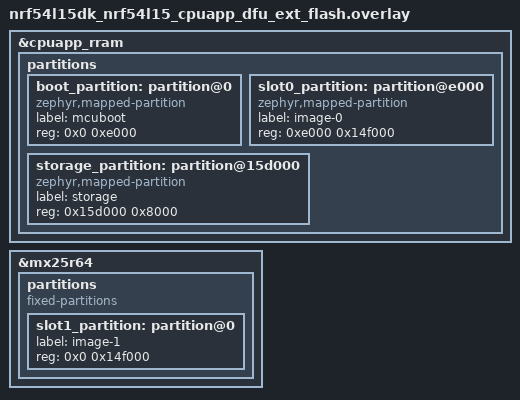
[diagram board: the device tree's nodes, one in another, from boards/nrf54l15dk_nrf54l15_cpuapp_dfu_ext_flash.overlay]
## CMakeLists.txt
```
# SPDX-License-Identifier: LicenseRef-Nordic-5-Clause

cmake_minimum_required(VERSION 3.13.1)
find_package(Zephyr REQUIRED HINTS $ENV{ZEPHYR_BASE})
project(mesh_dfu_distributor)

set(dfu_common_dir ${ZEPHYR_NRF_MODULE_DIR}/samples/bluetooth/mesh/dfu/common/src)

include_directories(
  ${dfu_common_dir}
  ${ZEPHYR_NRF_MODULE_DIR}/samples/bluetooth/mesh/common
)

FILE(GLOB app_sources src/*.c)
target_sources(app PRIVATE ${app_sources}
  ${ZEPHYR_NRF_MODULE_DIR}/samples/bluetooth/mesh/common/smp_bt.c
  ${ZEPHYR_NRF_MODULE_DIR}/samples/bluetooth/mesh/common/mgmt_dfu_hooks.c
  ${dfu_common_dir}/dfu_target.c
)

# Enable authentication with passkey
if(CONFIG_MCUMGR_TRANSPORT_BT_PERM_RW_AUTHEN AND CONFIG_BT_MESH_LE_PAIR_RESP)
  target_sources(app PRIVATE ${ZEPHYR_NRF_MODULE_DIR}/samples/bluetooth/mesh/common/smp_bt_auth.c)
endif()

target_link_libraries(app PRIVATE MCUBOOT_BOOTUTIL)
```

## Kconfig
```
source "Kconfig.zephyr"

source "${ZEPHYR_NRF_MODULE_DIR}/samples/bluetooth/mesh/common/Kconfig"
```

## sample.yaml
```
sample:
  name: Bluetooth Mesh DFU Distributor
common:
  tags:
    - bluetooth
    - ci_build
    - sysbuild
    - ci_samples_bluetooth
tests:
  sample.bluetooth.mesh_dfu_distributor:
    sysbuild: true
    build_only: true
    integration_platforms:
      - nrf54l15dk/nrf54l15/cpuapp
    platform_allow:
      - nrf54l15dk/nrf54l15/cpuapp
      - nrf54l15dk/nrf54l10/cpuapp
      - nrf54lm20dk/nrf54lm20a/cpuapp
  sample.bluetooth.mesh_dfu_distributor.smp_bt_auth:
    sysbuild: true
    build_only: true
    integration_platforms:
      - nrf54l15dk/nrf54l15/cpuapp
    platform_allow:
      - nrf54l15dk/nrf54l15/cpuapp
      - nrf54l15dk/nrf54l10/cpuapp
      - nrf54lm20dk/nrf54lm20a/cpuapp
    extra_args: OVERLAY_CONFIG=overlay-smp-bt-auth.conf
  sample.bluetooth.mesh_dfu_distributor.dfu_ext_flash:
    sysbuild: true
    build_only: true
    integration_platforms:
      - nrf54l15dk/nrf54l15/cpuapp
    platform_allow:
      - nrf54l15dk/nrf54l15/cpuapp
    extra_args: FILE_SUFFIX=dfu_ext_flash
  sample.bluetooth.mesh_dfu_distributor.settings_ext_flash:
    sysbuild: true
    build_only: true
    integration_platforms:
      - nrf54l15dk/nrf54l15/cpuapp
    platform_allow:
      - nrf54l15dk/nrf54l15/cpuapp
      - nrf54l15dk/nrf54l10/cpuapp
    extra_args: FILE_SUFFIX=settings_ext_flash
```

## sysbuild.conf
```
#
# Copyright (c) 2023 Nordic Semiconductor
#
# SPDX-License-Identifier: LicenseRef-Nordic-5-Clause
#

SB_CONFIG_BOOTLOADER_MCUBOOT=y
SB_CONFIG_DFU_ZIP=y
SB_CONFIG_DFU_ZIP_BLUETOOTH_MESH_METADATA=y
SB_CONFIG_DFU_ZIP_BLUETOOTH_MESH_METADATA_FWID_MCUBOOT_VERSION=y
```

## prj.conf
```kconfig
#
# Copyright (c) 2022 Nordic Semiconductor ASA
#
# SPDX-License-Identifier: LicenseRef-Nordic-5-Clause
#

# General configuration
CONFIG_SYSTEM_WORKQUEUE_STACK_SIZE=2048
CONFIG_NVS=y
CONFIG_SETTINGS=y
CONFIG_NVS_LOOKUP_CACHE=y
CONFIG_SETTINGS_NVS_NAME_CACHE=y
CONFIG_HWINFO=y
CONFIG_DK_LIBRARY=y
CONFIG_LOG=y

# Bootloader configuration
CONFIG_NCS_APPLICATION_BOOT_BANNER_STRING="Mesh DFU Distributor"
CONFIG_BOOTLOADER_MCUBOOT=y
CONFIG_NCS_SAMPLE_MCUMGR_BT_OTA_DFU=y
CONFIG_MCUMGR_TRANSPORT_WORKQUEUE_STACK_SIZE=3072
CONFIG_MCUBOOT_GENERATE_CONFIRMED_IMAGE=y
CONFIG_MCUBOOT_IMGTOOL_SIGN_VERSION="1.0.0+0"

# Enable MCUmgr command hooks for doing mesh reset when doing dfu upgrade and storage erase
CONFIG_MCUMGR_MGMT_NOTIFICATION_HOOKS=y
CONFIG_MCUMGR_SMP_COMMAND_STATUS_HOOKS=y
CONFIG_MCUMGR_GRP_OS_RESET_HOOK=y

# Bluetooth configuration
CONFIG_BT=y
CONFIG_BT_DEVICE_NAME="Mesh DFU Distributor"
CONFIG_BT_L2CAP_TX_BUF_COUNT=8
CONFIG_BT_OBSERVER=y
CONFIG_BT_PERIPHERAL=y
CONFIG_BT_SETTINGS=y
CONFIG_BT_BUF_CMD_TX_COUNT=4

# Disable unused Bluetooth features
CONFIG_BT_CTLR_LE_ENC=n
CONFIG_BT_DATA_LEN_UPDATE=n
CONFIG_BT_PHY_UPDATE=n
CONFIG_BT_CTLR_CHAN_SEL_2=n
CONFIG_BT_CTLR_PRIVACY=n
CONFIG_BT_CTLR_PHY_2M=n

# Bluetooth Mesh configuration
CONFIG_BT_MESH=y
CONFIG_BT_MESH_RELAY=y
CONFIG_BT_MESH_FRIEND=y
CONFIG_BT_MESH_MSG_CACHE_SIZE=256
CONFIG_BT_MESH_ADV_BUF_COUNT=128
CONFIG_BT_MESH_TX_SEG_MAX=14
CONFIG_BT_MESH_RX_SEG_MAX=14
CONFIG_BT_MESH_TX_SEG_MSG_COUNT=2
CONFIG_BT_MESH_RX_SEG_MSG_COUNT=2
CONFIG_BT_MESH_PB_GATT=y
CONFIG_BT_MESH_PB_ADV=y
CONFIG_BT_MESH_GATT_PROXY=y
CONFIG_BT_MESH_SHELL=y
CONFIG_BT_MESH_DK_PROV=y
# Force disconnect after PB-GATT provisioning for proper Proxy transition after DFU
CONFIG_BT_MESH_DK_PROV_PB_GATT_DISCONNECT=y
CONFIG_BT_MESH_PROXY_USE_DEVICE_NAME=y
CONFIG_BT_MESH_MODEL_EXTENSIONS=y
CONFIG_BT_MESH_MODEL_EXTENSION_LIST_SIZE=3

# Bluetooth Mesh models
CONFIG_BT_MESH_BLOB_SRV=y
CONFIG_BT_MESH_BLOB_IO_FLASH=y
CONFIG_BT_MESH_BLOB_CLI=y
CONFIG_BT_MESH_DFU_SRV=y
CONFIG_BT_MESH_DFU_METADATA=y
CONFIG_BT_MESH_DFU_CLI=y
CONFIG_BT_MESH_DFD_SRV=y
CONFIG_BT_MESH_SAR_CFG_SRV=y

# Reconfigure transport SAR for DFU
# Increase probability of delivering segmented messages
CONFIG_BT_MESH_SAR_TX_UNICAST_RETRANS_COUNT=0x5
CONFIG_BT_MESH_SAR_TX_UNICAST_RETRANS_WITHOUT_PROG_COUNT=0x3
# Reduce amount of generated SegAcks
CONFIG_BT_MESH_SAR_RX_ACK_RETRANS_COUNT=0x0
CONFIG_BT_MESH_SAR_RX_ACK_DELAY_INC=0x7
CONFIG_BT_MESH_SAR_RX_SEG_INT_STEP=0xf
CONFIG_BT_MESH_SAR_RX_SEG_THRESHOLD=0x1f

# Debug configuration
CONFIG_LOG_BACKEND_UART=y
CONFIG_BT_MESH_LOG_LEVEL_DBG=y
CONFIG_BT_MESH_MODEL_LOG_LEVEL_DBG=y
CONFIG_BT_MESH_DFU_LOG_LEVEL_DBG=y
CONFIG_BT_MESH_PROVISIONEE_LOG_LEVEL_INF=y

# Additional simultaneous connections for SMP BT.
CONFIG_BT_MAX_CONN=3
CONFIG_BT_CTLR_ADV_SET=6
CONFIG_BT_EXT_ADV_MAX_ADV_SET=6

# One extra identity for SMP service
CONFIG_BT_ID_MAX=2

# MCUmgr shell support
CONFIG_SHELL_BACKEND_SERIAL=n
CONFIG_SHELL_BACKEND_RTT=y
CONFIG_MCUMGR_GRP_SHELL=y
CONFIG_SHELL_BACKEND_DUMMY=y
CONFIG_SHELL_BACKEND_DUMMY_BUF_SIZE=1000
CONFIG_SEGGER_RTT_BUFFER_SIZE_DOWN=100

# MCUmgr UART transport
CONFIG_BASE64=y
CONFIG_UART_MCUMGR=y
CONFIG_MCUMGR_TRANSPORT_UART=y

# This option may not be enabled automatically for some boards. Enabling it explicitly to avoid
# missing configuration.
CONFIG_USE_SEGGER_RTT=y

# Link Time Optimization. CONFIG_LTO depends on ISR_TABLES_LOCAL_DECLARATION
CONFIG_LTO=y
CONFIG_ISR_TABLES_LOCAL_DECLARATION=y
```

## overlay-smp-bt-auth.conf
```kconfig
CONFIG_MCUMGR_TRANSPORT_BT_PERM_RW_AUTHEN=y
CONFIG_BT_SMP=y
CONFIG_BT_APP_PASSKEY=y
CONFIG_BT_MESH_LE_PAIR_RESP=y
CONFIG_BT_SMP_SC_ONLY=y
CONFIG_BT_SMP_ALLOW_UNAUTH_OVERWRITE=n
```

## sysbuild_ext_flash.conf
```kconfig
#
# Copyright (c) 2025 Nordic Semiconductor
#
# SPDX-License-Identifier: LicenseRef-Nordic-5-Clause
#

SB_CONFIG_BOOTLOADER_MCUBOOT=y
SB_CONFIG_PM_EXTERNAL_FLASH_MCUBOOT_SECONDARY=y
SB_CONFIG_DFU_ZIP=y
SB_CONFIG_DFU_ZIP_BLUETOOTH_MESH_METADATA=y
SB_CONFIG_DFU_ZIP_BLUETOOTH_MESH_METADATA_FWID_MCUBOOT_VERSION=y
```

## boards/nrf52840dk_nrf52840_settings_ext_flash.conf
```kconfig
#
# Copyright (c) 2025 Nordic Semiconductor ASA
#
# SPDX-License-Identifier: LicenseRef-Nordic-5-Clause
#

# External flash support for nRF52840 DK
CONFIG_NORDIC_QSPI_NOR=y

# Relocate settings partition to external flash
CONFIG_PM_PARTITION_REGION_SETTINGS_STORAGE_EXTERNAL=y
CONFIG_PM_PARTITION_SIZE_SETTINGS_STORAGE=0x8000
```

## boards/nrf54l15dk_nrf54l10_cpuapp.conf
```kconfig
#
# Copyright (c) 2024 Nordic Semiconductor ASA
#
# SPDX-License-Identifier: LicenseRef-Nordic-5-Clause
#
################################################################################
# Application overlay - nrf54l10

CONFIG_SOC_FLASH_NRF_PARTIAL_ERASE=n
CONFIG_NVS=n
CONFIG_NVS_LOOKUP_CACHE=n
CONFIG_SETTINGS_NVS_NAME_CACHE=n
CONFIG_ZMS=y
CONFIG_SETTINGS_ZMS_CUSTOM_SECTOR_COUNT=y
CONFIG_SETTINGS_ZMS_SECTOR_COUNT=8
CONFIG_ZMS_LOOKUP_CACHE=y
CONFIG_ZMS_LOOKUP_CACHE_SIZE=512
CONFIG_ZMS_LOOKUP_CACHE_FOR_SETTINGS=y
CONFIG_SYSTEM_WORKQUEUE_STACK_SIZE=4096
CONFIG_BT_RX_STACK_SIZE=5120
CONFIG_SHELL_STACK_SIZE=2560
```

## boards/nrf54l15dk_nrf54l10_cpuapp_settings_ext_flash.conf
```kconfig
#
# Copyright (c) 2025 Nordic Semiconductor ASA
#
# SPDX-License-Identifier: LicenseRef-Nordic-5-Clause
#
################################################################################
# Application overlay - nrf54l10

CONFIG_SOC_FLASH_NRF_PARTIAL_ERASE=n
CONFIG_NVS=n
CONFIG_NVS_LOOKUP_CACHE=n
CONFIG_SETTINGS_NVS_NAME_CACHE=n
CONFIG_ZMS=y
CONFIG_SETTINGS_ZMS_CUSTOM_SECTOR_COUNT=y
CONFIG_SETTINGS_ZMS_SECTOR_COUNT=8
CONFIG_ZMS_LOOKUP_CACHE=y
CONFIG_ZMS_LOOKUP_CACHE_SIZE=512
CONFIG_ZMS_LOOKUP_CACHE_FOR_SETTINGS=y
CONFIG_SYSTEM_WORKQUEUE_STACK_SIZE=4096
CONFIG_BT_RX_STACK_SIZE=5120
CONFIG_BT_MESH_SETTINGS_WORKQ_STACK_SIZE=1800
CONFIG_SHELL_STACK_SIZE=2560

# External flash specific settings
CONFIG_GPIO=y
CONFIG_SPI=y
CONFIG_SPI_NOR=y
CONFIG_SPI_NOR_SFDP_DEVICETREE=y
CONFIG_SPI_NOR_FLASH_LAYOUT_PAGE_SIZE=4096
# QSPI drivers are enabled by default for some chips.
# Disable it explicitly to be sure QSPI is disabled.
CONFIG_NORDIC_QSPI_NOR=n
```

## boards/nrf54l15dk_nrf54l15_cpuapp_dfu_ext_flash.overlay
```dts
/*
 * Copyright (c) 2026 Nordic Semiconductor ASA
 *
 * SPDX-License-Identifier: LicenseRef-Nordic-5-Clause
 */

/delete-node/ &boot_partition;
/delete-node/ &slot0_partition;
/delete-node/ &slot1_partition;
/delete-node/ &storage_partition;

&cpuapp_rram {
	partitions {
		boot_partition: partition@0 {
			compatible = "zephyr,mapped-partition";
			label = "mcuboot";
			reg = <0x0 0xe000>;
		};

		slot0_partition: partition@e000 {
			compatible = "zephyr,mapped-partition";
			label = "image-0";
			reg = <0xe000 0x14f000>;
		};

		storage_partition: partition@15d000 {
			compatible = "zephyr,mapped-partition";
			label = "storage";
			reg = <0x15d000 0x8000>;
		};
	};
};

&mx25r64 {
	status = "okay";

	partitions {
		compatible = "fixed-partitions";
		#address-cells = <1>;
		#size-cells = <1>;

		slot1_partition: partition@0 {
			label = "image-1";
			reg = <0x0 0x14f000>;
		};
	};
};
```

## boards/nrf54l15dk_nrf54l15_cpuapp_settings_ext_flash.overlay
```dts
/*
 * Copyright (c) 2026 Nordic Semiconductor ASA
 *
 * SPDX-License-Identifier: LicenseRef-Nordic-5-Clause
 */

/delete-node/ &boot_partition;
/delete-node/ &slot0_partition;
/delete-node/ &slot1_partition;
/delete-node/ &storage_partition;

&cpuapp_rram {
	partitions {
		boot_partition: partition@0 {
			compatible = "zephyr,mapped-partition";
			label = "mcuboot";
			reg = <0x0 0xe000>;
		};

		slot0_partition: partition@e000 {
			compatible = "zephyr,mapped-partition";
			label = "image-0";
			reg = <0xe000 0xa7000>;
		};

		slot1_partition: partition@b5000 {
			compatible = "zephyr,mapped-partition";
			label = "image-1";
			reg = <0xb5000 0xa7000>;
		};
	};
};

&mx25r64 {
	status = "okay";

	partitions {
		compatible = "fixed-partitions";
		#address-cells = <1>;
		#size-cells = <1>;

		storage_partition: partition@0 {
			label = "storage";
			reg = <0x0 0x8000>;
		};
	};
};
```

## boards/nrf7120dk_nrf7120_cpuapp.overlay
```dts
/*
 * Copyright (c) 2026 Nordic Semiconductor ASA
 *
 * SPDX-License-Identifier: LicenseRef-Nordic-5-Clause
 */

/*
 * The Bluetooth Mesh DFU distributor uses MCUboot with two image slots so it
 * can receive and store a new firmware image before swapping. The default
 * nRF7120 image slots (1440K each) are too large to leave room for both slots
 * plus the settings storage, so the layout is redefined with smaller MCUboot
 * and image-slot partitions. The Wi-Fi LMAC/UMAC ROM-patch partitions
 * (0x2e0000 / 0x2f0000) and the "storage" partition (36K at the end of MRAM)
 * keep their default board addresses.
 */
&cpuapp_mram {
	/delete-node/ partitions;

	partitions {
		#address-cells = <1>;
		#size-cells = <1>;
		ranges;

		boot_partition: partition@0 {
			compatible = "zephyr,mapped-partition";
			label = "mcuboot";
			reg = <0x0 DT_SIZE_K(56)>;
		};

		slot0_partition: partition@e000 {
			compatible = "zephyr,mapped-partition";
			label = "image-0";
			reg = <0xe000 DT_SIZE_K(924)>;
		};

		slot1_partition: partition@f5000 {
			compatible = "zephyr,mapped-partition";
			label = "image-1";
			reg = <0xf5000 DT_SIZE_K(924)>;
		};

		wifi_lmac_patch_partition: partition@2e0000 {
			compatible = "zephyr,mapped-partition";
			reg = <0x2e0000 DT_SIZE_K(4)>;
		};

		wifi_umac_patch_partition: partition@2f0000 {
			compatible = "zephyr,mapped-partition";
			reg = <0x2f0000 DT_SIZE_K(4)>;
		};

		storage_partition: partition@300000 {
			compatible = "zephyr,mapped-partition";
			label = "storage";
			reg = <0x300000 DT_SIZE_K(36)>;
		};
	};
};
```

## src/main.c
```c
/*
 * Copyright (c) 2022 Nordic Semiconductor ASA
 *
 * SPDX-License-Identifier: LicenseRef-Nordic-5-Clause
 */

/** @file
 *  @brief Bluetooth Mesh DFU Distributor role sample
 */
#include <zephyr/kernel.h>
#include <zephyr/storage/flash_map.h>
#include <zephyr/bluetooth/bluetooth.h>
#include <zephyr/bluetooth/mesh.h>
#include <bluetooth/mesh/vnd/le_pair_resp.h>
#include <bluetooth/mesh/dk_prov.h>
#include <dk_buttons_and_leds.h>
#include "smp_bt.h"
#include "dfu_dist.h"
#include "dfu_target.h"

static struct bt_mesh_blob_io_flash blob_flash_stream;

/* Set up a repeating delayed work to blink the DK's LEDs when attention is
 * requested.
 */
static struct k_work_delayable attention_blink_work;
static bool attention;

static void attention_blink(struct k_work *work)
{
	static int idx;
	const uint8_t pattern[] = {
#if DT_NODE_EXISTS(DT_ALIAS(led0))
		BIT(0),
#endif
#if DT_NODE_EXISTS(DT_ALIAS(led1))
		BIT(1),
#endif
#if DT_NODE_EXISTS(DT_ALIAS(led2))
		BIT(2),
#endif
#if DT_NODE_EXISTS(DT_ALIAS(led3))
		BIT(3),
#endif
	};

	if (attention) {
		dk_set_leds(pattern[idx++ % ARRAY_SIZE(pattern)]);
		k_work_reschedule(&attention_blink_work, K_MSEC(30));
	} else {
		dk_set_leds(DK_NO_LEDS_MSK);
	}
}

static void attention_on(const struct bt_mesh_model *mod)
{
	attention = true;
	k_work_reschedule(&attention_blink_work, K_NO_WAIT);
}

static void attention_off(const struct bt_mesh_model *mod)
{
	/* Will stop rescheduling blink timer */
	attention = false;
}

static const struct bt_mesh_health_srv_cb health_srv_cb = {
	.attn_on = attention_on,
	.attn_off = attention_off,
};

static struct bt_mesh_health_srv health_srv = {
	.cb = &health_srv_cb,
};

BT_MESH_HEALTH_PUB_DEFINE(health_pub, 0);

static struct bt_mesh_model primary_models[] = {
	BT_MESH_MODEL_CFG_SRV,
	BT_MESH_MODEL_HEALTH_SRV(&health_srv, &health_pub),
	BT_MESH_MODEL_DFD_SRV(&dfd_srv),
};

static struct bt_mesh_model primary_vnd_models[] = {
#if CONFIG_BT_MESH_LE_PAIR_RESP
	BT_MESH_MODEL_LE_PAIR_RESP,
#endif
};

static struct bt_mesh_model secondary_models[] = {
	BT_MESH_MODEL_DFU_SRV(&dfu_srv),
};

static struct bt_mesh_elem elements[] = {
	BT_MESH_ELEM(1, primary_models, primary_vnd_models),
	BT_MESH_ELEM(2, secondary_models, BT_MESH_MODEL_NONE),
};

static const struct bt_mesh_comp comp = {
	.cid = CONFIG_BT_COMPANY_ID,
	.elem = elements,
	.elem_count = ARRAY_SIZE(elements),
};

static void bt_ready(int err)
{
	if (err) {
		printk("Bluetooth init failed (err %d)\n", err);
		return;
	}

	printk("Bluetooth initialized\n");

	err = dk_leds_init();
	if (err) {
		printk("Initializing LEDs failed (err %d)\n", err);
		return;
	}

	err = bt_mesh_init(bt_mesh_dk_prov_init(), &comp);
	if (err) {
		printk("Initializing mesh failed (err %d)\n", err);
		return;
	}

	if (IS_ENABLED(CONFIG_SETTINGS)) {
		settings_load();
	}

	bt_mesh_prov_enable(BT_MESH_PROV_ADV | BT_MESH_PROV_GATT);

	printk("Mesh initialized\n");

	/* Start advertising SMP BT service. */
	err = smp_dfu_init();
	if (err) {
		printk("SMP initialization failed (err: %d)\n", err);
	}

	/* Confirm the image and mark it as applied after the mesh started. */
	dfu_target_image_confirm();
}

int main(void)
{
	int err;

	printk("Initializing...\n");

	err = bt_mesh_blob_io_flash_init(&blob_flash_stream, PARTITION_ID(slot1_partition),
					 0);
	if (err) {
		printk("Failed to init BLOB IO Flash module: %d\n", err);
		return 1;
	}

	k_work_init_delayable(&attention_blink_work, attention_blink);
	dfu_distributor_init(&blob_flash_stream);
	dfu_target_init(&blob_flash_stream);

	err = bt_enable(bt_ready);
	if (err) {
		printk("Bluetooth init failed (err %d)\n", err);
		return 2;
	}
	return 0;
}
```

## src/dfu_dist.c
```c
/*
 * Copyright (c) 2022 Nordic Semiconductor ASA
 *
 * SPDX-License-Identifier: LicenseRef-Nordic-5-Clause
 */

#include "dfu_dist.h"

static struct bt_mesh_blob_io_flash *blob_flash_stream;

static void slot_info_print(const struct bt_mesh_dfu_slot *slot, const uint8_t *idx)
{
	char fwid[2 * CONFIG_BT_MESH_DFU_FWID_MAXLEN + 1];
	char metadata[2 * CONFIG_BT_MESH_DFU_METADATA_MAXLEN + 1];
	size_t len;

	len = bin2hex(slot->fwid, slot->fwid_len, fwid, sizeof(fwid));
	fwid[len] = '\0';
	len = bin2hex(slot->metadata, slot->metadata_len, metadata,
		      sizeof(metadata));
	metadata[len] = '\0';

	if (idx != NULL) {
		printk("Slot %u:\n", *idx);
	} else {
		printk("Slot:\n");
	}
	printk("\tSize:     %u bytes\n", slot->size);
	printk("\tFWID:     %s\n", fwid);
	printk("\tMetadata: %s\n", metadata);
}

static int dfd_srv_recv(struct bt_mesh_dfd_srv *srv,
			const struct bt_mesh_dfu_slot *slot,
			const struct bt_mesh_blob_io **io)
{
	printk("Uploading new firmware image to the distributor.\n");
	slot_info_print(slot, NULL);

	*io = &blob_flash_stream->io;

	return 0;
}

static void dfd_srv_del(struct bt_mesh_dfd_srv *srv,
			const struct bt_mesh_dfu_slot *slot)
{
	printk("Deleting the firmware image from the distributor.\n");
	slot_info_print(slot, NULL);
}

static int dfd_srv_send(struct bt_mesh_dfd_srv *srv,
			const struct bt_mesh_dfu_slot *slot,
			const struct bt_mesh_blob_io **io)
{
	printk("Starting the firmware distribution.\n");
	slot_info_print(slot, NULL);

	*io = &blob_flash_stream->io;

	return 0;
}

static const char *dfd_phase_to_str(enum bt_mesh_dfd_phase phase)
{
	switch (phase) {
	case BT_MESH_DFD_PHASE_IDLE:
		return "Idle";
	case BT_MESH_DFD_PHASE_TRANSFER_ACTIVE:
		return "Transfer Active";
	case BT_MESH_DFD_PHASE_TRANSFER_SUCCESS:
		return "Transfer Success";
	case BT_MESH_DFD_PHASE_APPLYING_UPDATE:
		return "Applying Update";
	case BT_MESH_DFD_PHASE_COMPLETED:
		return "Completed";
	case BT_MESH_DFD_PHASE_FAILED:
		return "Failed";
	case BT_MESH_DFD_PHASE_CANCELING_UPDATE:
		return "Canceling Update";
	case BT_MESH_DFD_PHASE_TRANSFER_SUSPENDED:
		return "Transfer Suspended";
	default:
		return "Unknown Phase";
	}
}

static void dfd_srv_phase(struct bt_mesh_dfd_srv *srv, enum bt_mesh_dfd_phase phase)
{
	printk("Distribution phase changed to %s\n", dfd_phase_to_str(phase));
}

static struct bt_mesh_dfd_srv_cb dfd_srv_cb = {
	.recv = dfd_srv_recv,
	.del = dfd_srv_del,
	.send = dfd_srv_send,
	.phase = dfd_srv_phase,
};

struct bt_mesh_dfd_srv dfd_srv = BT_MESH_DFD_SRV_INIT(&dfd_srv_cb);

void dfu_distributor_init(struct bt_mesh_blob_io_flash *flash_stream)
{
	blob_flash_stream = flash_stream;
}
```

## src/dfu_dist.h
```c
/*
 * Copyright (c) 2022 Nordic Semiconductor ASA
 *
 * SPDX-License-Identifier: LicenseRef-Nordic-5-Clause
 */

#ifndef DFU_DIST_H__
#define DFU_DIST_H__

#include <zephyr/bluetooth/mesh.h>

#ifdef __cplusplus
extern "C" {
#endif

extern struct bt_mesh_dfd_srv dfd_srv;

void dfu_distributor_init(struct bt_mesh_blob_io_flash *flash_stream);

#ifdef __cplusplus
}
#endif

#endif /* DFU_DIST_H__ */
```
